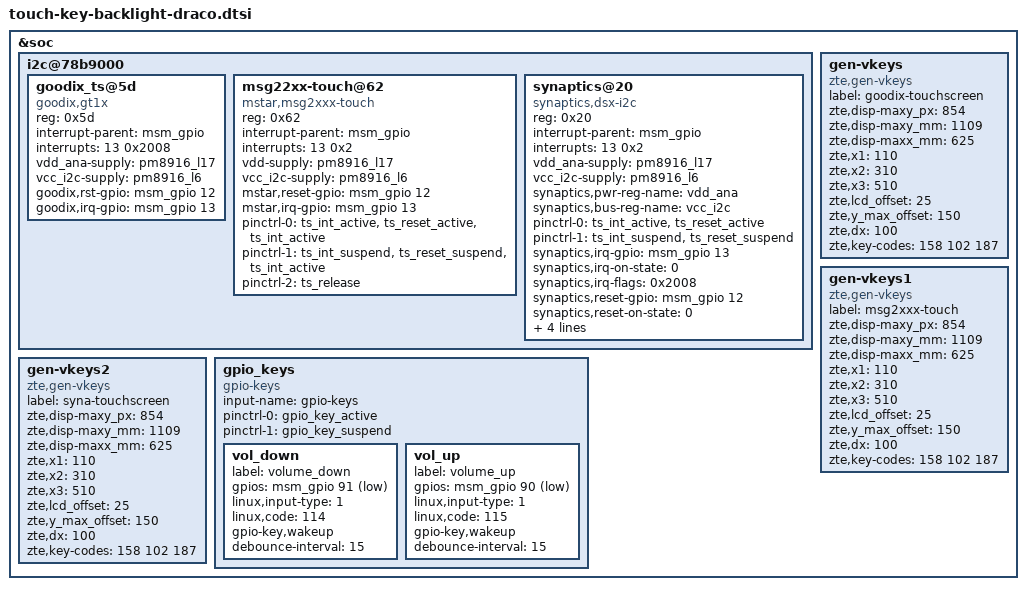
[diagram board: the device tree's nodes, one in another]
&soc {
	i2c@78b9000 { /* BLSP1 QUP5 */
		goodix_ts@5d {
			compatible = "goodix,gt1x";
			reg = <0x5d>;
			interrupt-parent = <&msm_gpio>;
			interrupts = <13 0x2008>;
			vdd_ana-supply = <&pm8916_l17>;
			vcc_i2c-supply = <&pm8916_l6>;
			goodix,rst-gpio = <&msm_gpio 12 0x00>;
			goodix,irq-gpio = <&msm_gpio 13 0x00>;
		};

		msg22xx-touch@62 {
			compatible = "mstar,msg2xxx-touch";
			reg = <0x62>;
			interrupt-parent = <&msm_gpio>;
			interrupts = <13 0x2>;
			vdd-supply = <&pm8916_l17>;
			vcc_i2c-supply = <&pm8916_l6>;
			mstar,reset-gpio = <&msm_gpio 12 0x00>;
			mstar,irq-gpio = <&msm_gpio 13 0x00>;
			pinctrl-names = "pmx_ts_active","pmx_ts_suspend", "pmx_ts_release";
			pinctrl-0 = <&ts_int_active &ts_reset_active &ts_int_active>;
			pinctrl-1 = <&ts_int_suspend &ts_reset_suspend &ts_int_active>;
			pinctrl-2 = <&ts_release>;
		};

		synaptics@20 {
			compatible = "synaptics,dsx-i2c";
			reg = <0x20>;
			interrupt-parent = <&msm_gpio>;
			interrupts = <13 0x2>;
			vdd_ana-supply = <&pm8916_l17>;
			vcc_i2c-supply = <&pm8916_l6>;
			synaptics,pwr-reg-name = "vdd_ana";
			synaptics,bus-reg-name = "vcc_i2c";
			/* pins used by touchscreen */
			pinctrl-names = "pmx_ts_active","pmx_ts_suspend";
			pinctrl-0 = <&ts_int_active &ts_reset_active>;
			pinctrl-1 = <&ts_int_suspend &ts_reset_suspend>;
			//synaptics,display-coords = <0 0 1079 1919>;
			//synaptics,panel-coords = <0 0 1079 2084>;
			synaptics,irq-gpio = <&msm_gpio 13 0x0>;
			synaptics,irq-on-state = <0>;
			synaptics,irq-flags = <0x2008>;
			synaptics,reset-gpio = <&msm_gpio 12 0x0>;
			synaptics,reset-on-state = <0>;
			synaptics,reset-delay-ms = <100>;
			synaptics,reset-active-ms = <20>;
			synaptics,power-delay-ms = <100>;
			synaptics,cap-button-codes = <158 102 187>;
		};
	};

	gen-vkeys {
		compatible = "zte,gen-vkeys";
		label = "goodix-touchscreen";
		zte,disp-maxy_px = <854>;
		zte,disp-maxy_mm = <1109>;
		zte,disp-maxx_mm = <625>;
		zte,x1=<110>;
		zte,x2=<310>;
		zte,x3=<510>;
		zte,lcd_offset=<25>;
		zte,y_max_offset=<150>;
		zte,dx=<100>;
		zte,key-codes = <158 102 187>;
	};

	gen-vkeys1 {
		compatible = "zte,gen-vkeys";
		label = "msg2xxx-touch";
		zte,disp-maxy_px = <854>;
		zte,disp-maxy_mm = <1109>;
		zte,disp-maxx_mm = <625>;
		zte,x1=<110>;
		zte,x2=<310>;
		zte,x3=<510>;
		zte,lcd_offset=<25>;
		zte,y_max_offset=<150>;
		zte,dx=<100>;
		zte,key-codes = <158 102 187>;
	};

	gen-vkeys2 {
		compatible = "zte,gen-vkeys";
		label = "syna-touchscreen";
		zte,disp-maxy_px = <854>;
		zte,disp-maxy_mm = <1109>;
		zte,disp-maxx_mm = <625>;
		zte,x1=<110>;
		zte,x2=<310>;
		zte,x3=<510>;
		zte,lcd_offset=<25>;
		zte,y_max_offset=<150>;
		zte,dx=<100>;
		zte,key-codes = <158 102 187>;
	};

	gpio_keys {
		compatible = "gpio-keys";
		input-name = "gpio-keys";
		pinctrl-names = "tlmm_gpio_key_active","tlmm_gpio_key_suspend";
		pinctrl-0 = <&gpio_key_active>;
		pinctrl-1 = <&gpio_key_suspend>;

		vol_down {
			label = "volume_down";
			gpios = <&msm_gpio 91 0x1>;
			linux,input-type = <1>;
			linux,code = <114>;
			gpio-key,wakeup;
			debounce-interval = <15>;
		};
		vol_up {
			label = "volume_up";
			gpios = <&msm_gpio 90 0x1>;
			linux,input-type = <1>;
			linux,code = <115>;
			gpio-key,wakeup;
			debounce-interval = <15>;
		};
	};

	/*gpio-leds {
		compatible = "gpio-leds";
		status = "okay";
		pinctrl-names = "default";
		pinctrl-0 = <&button_backlight_off>;

		keypad-backlight {
			gpios = <&msm_gpio 97 0>;
			label = "button-backlight";
			linux,default-trigger = "none";
		};
	};*/
};
